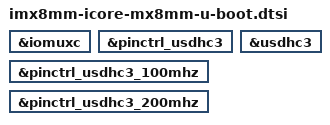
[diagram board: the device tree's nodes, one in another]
// SPDX-License-Identifier: (GPL-2.0+ OR MIT)
/*
 * Copyright (c) 2020 Engicam srl
 * Copyright (c) 2020 Amarula Solutions(India)
 */

#include "imx8mm-u-boot.dtsi"

&iomuxc {
	bootph-pre-ram;
};

&pinctrl_usdhc3 {
	bootph-pre-ram;
};

&pinctrl_usdhc3_100mhz {
	bootph-pre-ram;
};

&pinctrl_usdhc3_200mhz {
	bootph-pre-ram;
};

&usdhc3 {
	bootph-pre-ram;
};
